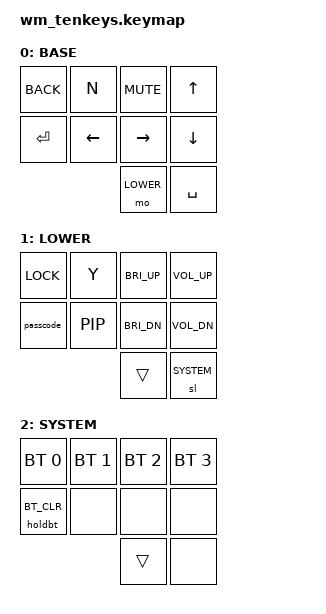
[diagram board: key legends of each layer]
#include <behaviors.dtsi>
#include <dt-bindings/zmk/keys.h>
#include <dt-bindings/zmk/bt.h>
#include <dt-bindings/zmk/outputs.h>

#define DEFAULT 0
#define LOWER   1
#define SYSTEM  2

&sl {
    release-after-ms = <2000>;
};

/ {
    behaviors {
        holdbt: hold_bt {
            compatible = "zmk,behavior-hold-tap";
            label = "HBT";
            #binding-cells = <2>;
            flavor = "tap-preferred";
            tapping-term-ms = <500>;
            quick-tap-ms = <200>;
            bindings = <&bt>, <&none>;
            hold-trigger-key-positions = <1>;
        };
    };

    macros {
        passcode: passcode {
            label = "PCODE";
            compatible = "zmk,behavior-macro";
            #binding-cells = <0>;
            bindings
                = <&macro_tap &kp N1 &kp N0 &kp N0 &kp N6>;
        };
    };

    keymap {
      compatible = "zmk,keymap";

      default_layer {
        bindings = <
          &kp K_BACK &kp N    &kp K_MUTE &kp UP
          &kp ENTER  &kp LEFT &kp RIGHT  &kp DOWN
                              &mo LOWER  &kp SPACE
                              >;
          label = "BASE";
      };

      lower_layer {
        bindings = <
          &kp K_LOCK &kp Y      &kp C_BRI_UP &kp K_VOL_UP
          &passcode  &kp C_PIP  &kp C_BRI_DN &kp K_VOL_DN
                            &trans       &sl SYSTEM
                              >;
          label = "LOWER";
      };

      system_layer {
        // -------------------------
        // | BT1 | BT2 | BT3   | BT4 |
        // | BTC |  -  |  -    |  -  |
        //             | trans |  -  |
        bindings = <
          &bt BT_SEL 0   &bt BT_SEL 1 &bt BT_SEL 2 &bt BT_SEL 3
          &holdbt BT_CLR &none        &none        &none
                                      &trans       &none
                              >;
          label = "SYSTEM";
      };

    };
};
